CM_ "Imported file _toyota_2017.dbc starts here"
VERSION ""

NS_ :

BS_:

BU_: XXX DSU HCU EPS IPAS

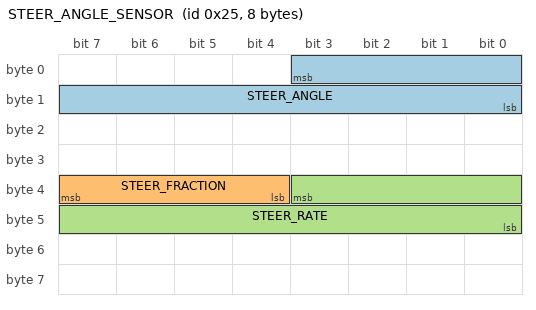
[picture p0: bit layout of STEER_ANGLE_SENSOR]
BO_ 37 STEER_ANGLE_SENSOR: 8 XXX
 SG_ STEER_ANGLE : 3|12@0- (1.5,0) [-500|500] "deg" XXX
 SG_ STEER_FRACTION : 39|4@0- (0.1,0) [-0.7|0.7] "deg" XXX
 SG_ STEER_RATE : 35|12@0- (1,0) [-2000|2000] "deg/s" XXX

CM_ SG_ 614 ANGLE "set to measured angle when ipas control isn't active";
CM_ SG_ 37 STEER_FRACTION "1/15th of the signal STEER_ANGLE, which is 1.5 deg; note that 0x8 is never set";
CM_ SG_ 37 STEER_RATE "factor is tbd";

VAL_ 466 CRUISE_STATE 8 "active" 7 "standstill" 1 "off" ;
VAL_ 467 LOW_SPEED_LOCKOUT 2 "low speed locked" 1 "ok" ;

CM_ "CHFFR_METRIC 37 STEER_ANGLE STEER_ANGLE 0.36 180";
